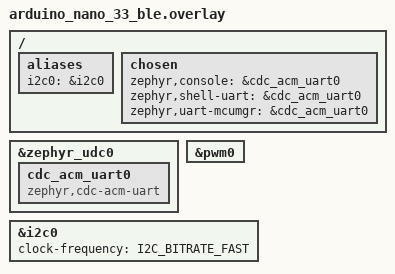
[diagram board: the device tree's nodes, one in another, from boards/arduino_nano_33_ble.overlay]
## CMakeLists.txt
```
cmake_minimum_required(VERSION 3.20.0)
find_package(Zephyr REQUIRED HINTS $ENV{ZEPHYR_BASE})
project(mini_beam_nrf52)

target_sources(app PRIVATE
  src/main.c
  ../src/mb_vm.c
  ../src/mb_scheduler.c
  ../src/mb_heap.c
  ../src/mb_hal_nrf52.c
)

target_include_directories(app PRIVATE ../include)

target_compile_definitions(app PRIVATE MB_USE_NRF52)
target_compile_definitions(app PRIVATE MB_STRICT_DTS)

if(DEFINED OS2_FAULT_EVERY_N)
  target_compile_definitions(app PRIVATE OS2_FAULT_EVERY_N=${OS2_FAULT_EVERY_N})
  message(STATUS "OS2_FAULT_EVERY_N=${OS2_FAULT_EVERY_N}")
endif()
```

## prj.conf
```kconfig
CONFIG_GPIO=y
CONFIG_PWM=y
CONFIG_I2C=y
CONFIG_SERIAL=y
CONFIG_UART_CONSOLE=y
CONFIG_LOG=y
CONFIG_LOG_MODE_DEFERRED=y
CONFIG_LOG_BUFFER_SIZE=2048
CONFIG_LOG_BACKEND_UART=y
CONFIG_CONSOLE=y
CONFIG_PRINTK=y
CONFIG_STDOUT_CONSOLE=y

# Keep runtime logs on the board USB CDC ACM interface (Nano 33 BLE).
CONFIG_USB_DEVICE_STACK=y
CONFIG_UART_LINE_CTRL=y
CONFIG_USB_CDC_ACM_RINGBUF_SIZE=2048

# Increase main stack for scheduler struct access paths.
CONFIG_MAIN_STACK_SIZE=8192

# Software task watchdog for runtime recovery.
CONFIG_TASK_WDT=y
CONFIG_REBOOT=y
```

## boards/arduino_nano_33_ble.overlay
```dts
/ {
    aliases {
        i2c0 = &i2c0;
    };

    chosen {
        zephyr,console = &cdc_acm_uart0;
        zephyr,shell-uart = &cdc_acm_uart0;
        zephyr,uart-mcumgr = &cdc_acm_uart0;
    };
};

&zephyr_udc0 {
    cdc_acm_uart0: cdc_acm_uart0 {
        compatible = "zephyr,cdc-acm-uart";
    };
};

&pwm0 {
    status = "okay";
};

&i2c0 {
    status = "okay";
    clock-frequency = <I2C_BITRATE_FAST>;
};
```

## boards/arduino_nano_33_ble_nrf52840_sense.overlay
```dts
/ {
    aliases {
        /* For Sense target, route logical i2c0 to onboard-sensor bus i2c1. */
        i2c0 = &i2c1;
    };

    chosen {
        zephyr,console = &cdc_acm_uart0;
        zephyr,shell-uart = &cdc_acm_uart0;
        zephyr,uart-mcumgr = &cdc_acm_uart0;
    };
};

&zephyr_udc0 {
    cdc_acm_uart0: cdc_acm_uart0 {
        compatible = "zephyr,cdc-acm-uart";
    };
};

&pwm0 {
    status = "okay";
};

&i2c1 {
    status = "okay";
    clock-frequency = <I2C_BITRATE_FAST>;
};
```

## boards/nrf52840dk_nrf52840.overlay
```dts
/ {
    aliases {
        i2c0 = &i2c0;
    };
};

&pwm0 {
    status = "okay";
};

&i2c0 {
    status = "okay";
    clock-frequency = <I2C_BITRATE_FAST>;
};
```

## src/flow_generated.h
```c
/* Generated by OS/II flow compiler -- do not edit */
#ifndef OS2_FLOW_GENERATED_H
#define OS2_FLOW_GENERATED_H

#define OS2_FLOW_SENSOR_COUNT 4
#define OS2_FLOW_PROCESS_COUNT 5
#define OS2_FLOW_MAILBOX_DEPTH 32
#define OS2_FLOW_WATCHDOG_MS 6000
#define OS2_FLOW_ON_FAIL "stop_actuator"

static const uint8_t os2_flow_sensor_prog_1[72] = {
    0x01, 0x00, 0x01, 0x00, 0x00, 0x00, 0x01, 0x01, 0x39, 0x00, 0x00, 0x00, 0x01,
    0x02, 0x92, 0x00, 0x00, 0x00, 0x01, 0x03, 0x05, 0x00, 0x00, 0x00, 0x01,
    0x04, 0x02, 0x00, 0x00, 0x00, 0x01, 0x05, 0x00, 0x00, 0x00, 0x00, 0x01,
    0x06, 0x00, 0x00, 0x00, 0x00, 0x01, 0x08, 0x00, 0x00, 0x00, 0x00, 0x10,
    0x03, 0x03, 0x00, 0x01, 0x02, 0x07, 0x10, 0x04, 0x00, 0x09, 0x21, 0x03,
    0x04, 0x05, 0x07, 0x08, 0x08, 0x23, 0x30, 0xE8, 0xFF, 0xFF, 0xFF
};
static const uint8_t os2_flow_sensor_prog_2[72] = {
    0x01, 0x00, 0x01, 0x00, 0x00, 0x00, 0x01, 0x01, 0x5F, 0x00, 0x00, 0x00, 0x01,
    0x02, 0x0F, 0x00, 0x00, 0x00, 0x01, 0x03, 0x05, 0x00, 0x00, 0x00, 0x01,
    0x04, 0x02, 0x00, 0x00, 0x00, 0x01, 0x05, 0x00, 0x00, 0x00, 0x00, 0x01,
    0x06, 0x00, 0x00, 0x00, 0x00, 0x01, 0x08, 0x00, 0x00, 0x00, 0x00, 0x10,
    0x03, 0x03, 0x00, 0x01, 0x02, 0x07, 0x10, 0x04, 0x00, 0x09, 0x21, 0x03,
    0x04, 0x05, 0x07, 0x08, 0x08, 0x23, 0x30, 0xE8, 0xFF, 0xFF, 0xFF
};
static const uint8_t os2_flow_sensor_prog_3[72] = {
    0x01, 0x00, 0x01, 0x00, 0x00, 0x00, 0x01, 0x01, 0x39, 0x00, 0x00, 0x00, 0x01,
    0x02, 0x92, 0x00, 0x00, 0x00, 0x01, 0x03, 0x05, 0x00, 0x00, 0x00, 0x01,
    0x04, 0x02, 0x00, 0x00, 0x00, 0x01, 0x05, 0x00, 0x00, 0x00, 0x00, 0x01,
    0x06, 0x00, 0x00, 0x00, 0x00, 0x01, 0x08, 0x00, 0x00, 0x00, 0x00, 0x10,
    0x03, 0x03, 0x00, 0x01, 0x02, 0x07, 0x10, 0x04, 0x00, 0x09, 0x21, 0x03,
    0x04, 0x05, 0x07, 0x08, 0x08, 0x23, 0x30, 0xE8, 0xFF, 0xFF, 0xFF
};
static const uint8_t os2_flow_sensor_prog_4[72] = {
    0x01, 0x00, 0x01, 0x00, 0x00, 0x00, 0x01, 0x01, 0x5F, 0x00, 0x00, 0x00, 0x01,
    0x02, 0x0F, 0x00, 0x00, 0x00, 0x01, 0x03, 0x05, 0x00, 0x00, 0x00, 0x01,
    0x04, 0x02, 0x00, 0x00, 0x00, 0x01, 0x05, 0x00, 0x00, 0x00, 0x00, 0x01,
    0x06, 0x00, 0x00, 0x00, 0x00, 0x01, 0x08, 0x00, 0x00, 0x00, 0x00, 0x10,
    0x03, 0x03, 0x00, 0x01, 0x02, 0x07, 0x10, 0x04, 0x00, 0x09, 0x21, 0x03,
    0x04, 0x05, 0x07, 0x08, 0x08, 0x23, 0x30, 0xE8, 0xFF, 0xFF, 0xFF
};

static const uint8_t *os2_flow_sensor_progs[] = {
    os2_flow_sensor_prog_1,
    os2_flow_sensor_prog_2,
    os2_flow_sensor_prog_3,
    os2_flow_sensor_prog_4
};
static const size_t os2_flow_sensor_sizes[] = {
    sizeof(os2_flow_sensor_prog_1), sizeof(os2_flow_sensor_prog_2), sizeof(os2_flow_sensor_prog_3), sizeof(os2_flow_sensor_prog_4)
};

static const uint8_t os2_flow_actuator_prog[17] = {
    0x20, 0x00, 0x01, 0x02, 0x03, 0x04, 0x10, 0x02, 0x02, 0x01, 0x02, 0x05, 0x30,
    0xEF, 0xFF, 0xFF, 0xFF
};

#endif
```
